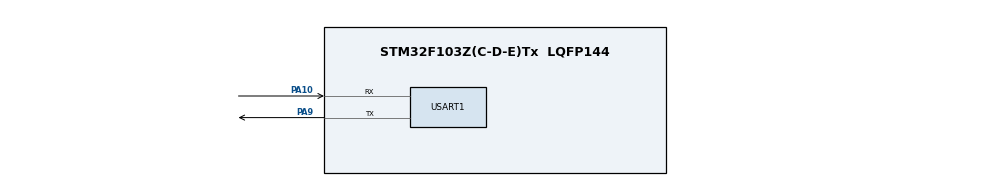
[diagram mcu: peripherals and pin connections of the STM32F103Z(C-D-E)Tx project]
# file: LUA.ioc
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Mcu.Family=STM32F1
Mcu.Name=STM32F103Z(C-D-E)Tx
Mcu.Package=LQFP144
NVIC.PriorityGroup=NVIC_PRIORITYGROUP_4
NVIC.USART1_IRQn=true\:0\:0\:false\:false\:true\:true\:true
OSC_IN.Mode=HSE-External-Oscillator
OSC_IN.Signal=RCC_OSC_IN
OSC_OUT.Mode=HSE-External-Oscillator
OSC_OUT.Signal=RCC_OSC_OUT
PA10.Mode=Asynchronous
PA10.Signal=USART1_RX
PA13.Mode=Serial_Wire
PA13.Signal=SYS_JTMS-SWDIO
PA14.Mode=Serial_Wire
PA14.Signal=SYS_JTCK-SWCLK
PA9.Mode=Asynchronous
PA9.Signal=USART1_TX
ProjectManager.HeapSize=0x200
ProjectManager.StackSize=0x400
ProjectManager.TargetToolchain=MDK-ARM V5
RCC.APB1Freq_Value=8000000
RCC.APB2Freq_Value=8000000
USART1.VirtualMode=VM_ASYNC
board=custom

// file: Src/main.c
/* USER CODE BEGIN Header */
/**
  ******************************************************************************
  * @file           : main.c
  * @brief          : Main program body
  ******************************************************************************
  * @attention
  *
  * <h2><center>&copy; Copyright (c) 2020 STMicroelectronics.
  * All rights reserved.</center></h2>
  *
  * This software component is licensed by ST under BSD 3-Clause license,
  * the "License"; You may not use this file except in compliance with the
  * License. You may obtain a copy of the License at:
  *                        opensource.org/licenses/BSD-3-Clause
  *
  ******************************************************************************
  */
/* USER CODE END Header */

#include "main.h"
#include "usart.h"
#include "gpio.h"

/* USER CODE BEGIN Includes */
#include "lua.h"
#include "lualib.h"
#include "lauxlib.h"
#include "string.h"
/* USER CODE END Includes */

/* USER CODE BEGIN PD */
#define LUA_MAXINPUT    512
#define LUA_PROMPT      "> "
#define LUA_PROMPT2     ">> "
/* USER CODE END PD */

void SystemClock_Config(void);

/* USER CODE BEGIN 0 */

/*
** lua_readline defines how to show a prompt and then read a line from
** the standard input.
** lua_saveline defines how to "save" a read line in a "history".
** lua_freeline defines how to free a line read by lua_readline.
*/
#if !defined(lua_readline)    /* { */

#define lua_readline(L,b,p) \
        ((void)L, fputs(p, stdout), fflush(stdout),  /* show prompt */ \
        fgets(b, LUA_MAXINPUT, stdin) != NULL)  /* get line */
#define lua_saveline(L,line)    { (void)L; (void)line; }
#define lua_freeline(L,b)    { (void)L; (void)b; }

#endif                /* } */

const char *progname = "lua";

/*
** Prints an error message, adding the program name in front of it
** (if present)
*/
static void l_message (const char *pname, const char *msg) {
    if (pname) printf("%s: ", pname);
    printf("%s\n", msg);
}

/*
** Message handler used to run all chunks
*/
static int msghandler (lua_State *L) {
    const char *msg = lua_tostring(L, 1);
    if (msg == NULL) {  /* is error object not a string? */
        if (luaL_callmeta(L, 1, "__tostring") &&  /* does it have a metamethod */
                lua_type(L, -1) == LUA_TSTRING)  /* that produces a string? */
            return 1;  /* that is the message */
        else
            msg = lua_pushfstring(L, "(error object is a %s value)",
                                  luaL_typename(L, 1));
    }
    luaL_traceback(L, L, msg, 1);  /* append a standard traceback */
    return 1;  /* return the traceback */
}

/*
** Check whether 'status' is not OK and, if so, prints the error
** message on the top of the stack. It assumes that the error object
** is a string, as it was either generated by Lua or by 'msghandler'.
*/
static int report (lua_State *L, int status) {
    if (status != LUA_OK) {
        const char *msg = lua_tostring(L, -1);
        l_message("lua", msg);
        lua_pop(L, 1);  /* remove message */
    }
    return status;
}

/*
** Interface to 'lua_pcall', which sets appropriate message function
** and C-signal handler. Used to run all chunks.
*/

static int docall (lua_State *L, int narg, int nres) {
    int status;
    int base = lua_gettop(L) - narg;  /* function index */
    lua_pushcfunction(L, msghandler);  /* push message handler */
    lua_insert(L, base);  /* put it under function and args */
    //globalL = L;  /* to be available to 'laction' */
    //signal(SIGINT, laction);  /* set C-signal handler */
    status = lua_pcall(L, narg, nres, base);
    //signal(SIGINT, SIG_DFL); /* reset C-signal handler */
    lua_remove(L, base);  /* remove message handler from the stack */
    return status;
}

static int dochunk (lua_State *L, int status) {
    if (status == LUA_OK) status = docall(L, 0, 0);
    return report(L, status);
}

static int dofile (lua_State *L, const char *name) {
    return dochunk(L, luaL_loadfile(L, name));
}

static int dostring (lua_State *L, const char *s, const char *name) {
    return dochunk(L, luaL_loadbuffer(L, s, strlen(s), name));
}

/*
** Returns the string to be used as a prompt by the interpreter.
*/
static const char *get_prompt (lua_State *L, int firstline) {
    const char *p;
    lua_getglobal(L, firstline ? "_PROMPT" : "_PROMPT2");
    p = lua_tostring(L, -1);
    if (p == NULL) p = (firstline ? LUA_PROMPT : LUA_PROMPT2);
    return p;
}

/* mark in error messages for incomplete statements */
#define EOFMARK        "<eof>"
#define marklen        (sizeof(EOFMARK)/sizeof(char) - 1)

/*
** Check whether 'status' signals a syntax error and the error
** message at the top of the stack ends with the above mark for
** incomplete statements.
*/
static int incomplete (lua_State *L, int status) {
    if (status == LUA_ERRSYNTAX) {
        size_t lmsg;
        const char *msg = lua_tolstring(L, -1, &lmsg);
        if (lmsg >= marklen && strcmp(msg + lmsg - marklen, EOFMARK) == 0) {
            lua_pop(L, 1);
            return 1;
        }
    }
    return 0;  /* else... */
}

/*
** Prompt the user, read a line, and push it into the Lua stack.
*/
static int pushline (lua_State *L, int firstline) {
    char buffer[LUA_MAXINPUT];
    char *b = buffer;
    size_t l;
    const char *prmt = get_prompt(L, firstline);
    int readstatus = lua_readline(L, b, prmt);
    if (readstatus == 0)
        return 0;  /* no input (prompt will be popped by caller) */
    lua_pop(L, 1);  /* remove prompt */
    l = strlen(b);
    if (l > 0 && b[l-1] == '\n')  /* line ends with newline? */
        b[--l] = '\0';  /* remove it */
    if (firstline && b[0] == '=')  /* for compatibility with 5.2, ... */
        lua_pushfstring(L, "return %s", b + 1);  /* change '=' to 'return' */
    else
        lua_pushlstring(L, b, l);
    lua_freeline(L, b);
    return 1;
}

/*
** Try to compile line on the stack as 'return <line>'; on return, stack
** has either compiled chunk or original line (if compilation failed).
*/
static int addreturn (lua_State *L) {
    int status;
    size_t len;
    const char *line;
    lua_pushliteral(L, "return ");
    lua_pushvalue(L, -2);  /* duplicate line */
    lua_concat(L, 2);  /* new line is "return ..." */
    line = lua_tolstring(L, -1, &len);
    if ((status = luaL_loadbuffer(L, line, len, "=stdin")) == LUA_OK) {
        lua_remove(L, -3);  /* remove original line */
        line += sizeof("return")/sizeof(char);  /* remove 'return' for history */
        if (line[0] != '\0')  /* non empty? */
            lua_saveline(L, line);  /* keep history */
    }
    else
        lua_pop(L, 2);  /* remove result from 'luaL_loadbuffer' and new line */
    return status;
}

/*
** Read multiple lines until a complete Lua statement
*/
static int multiline (lua_State *L) {
    for (;;) {  /* repeat until gets a complete statement */
        size_t len;
        const char *line = lua_tolstring(L, 1, &len);  /* get what it has */
        int status = luaL_loadbuffer(L, line, len, "=stdin");  /* try it */
        if (!incomplete(L, status) || !pushline(L, 0)) {
            lua_saveline(L, line);  /* keep history */
            return status;  /* cannot or should not try to add continuation line */
        }
        lua_pushliteral(L, "\n");  /* add newline... */
        lua_insert(L, -2);  /* ...between the two lines */
        lua_concat(L, 3);  /* join them */
    }
}

/*
** Read a line and try to load (compile) it first as an expression (by
** adding "return " in front of it) and second as a statement. Return
** the final status of load/call with the resulting function (if any)
** in the top of the stack.
*/
static int loadline (lua_State *L) {
    int status;
    lua_settop(L, 0);
    if (!pushline(L, 1))
        return -1;  /* no input */
    if ((status = addreturn(L)) != LUA_OK)  /* 'return ...' did not work? */
        status = multiline(L);  /* try as command, maybe with continuation lines */
    lua_remove(L, 1);  /* remove line from the stack */
    lua_assert(lua_gettop(L) == 1);
    return status;
}

/*
** Prints (calling the Lua 'print' function) any values on the stack
*/
static void l_print (lua_State *L) {
    int n = lua_gettop(L);
    if (n > 0) {  /* any result to be printed? */
        luaL_checkstack(L, LUA_MINSTACK, "too many results to print");
        lua_getglobal(L, "print");
        lua_insert(L, 1);
        if (lua_pcall(L, n, 0, 0) != LUA_OK)
            l_message(progname, lua_pushfstring(L, "error calling 'print' (%s)",
                                                lua_tostring(L, -1)));
    }
}

/*
** Do the REPL: repeatedly read (load) a line, evaluate (call) it, and
** print any results.
*/
static void doREPL (lua_State *L) {
    int status;
    const char *oldprogname = progname;
    progname = NULL;  /* no 'progname' on errors in interactive mode */
    while ((status = loadline(L)) != -1) {
        if (status == LUA_OK)
            status = docall(L, 0, LUA_MULTRET);
        if (status == LUA_OK) l_print(L);
        else report(L, status);
    }
    lua_settop(L, 0);  /* clear stack */
    lua_writeline();
    progname = oldprogname;
}

static void print_version (void) {
    lua_writestring(LUA_COPYRIGHT, strlen(LUA_COPYRIGHT));
    lua_writeline();
}

void lua_main(void)
{
    l_message("lua", "welcome !!!\n");
    lua_State *L = luaL_newstate();  /* create state */
    if (L == NULL) {
        l_message("lua", "cannot create state: not enough memory\n");
        return ;
    }
    luaL_openlibs(L);
    print_version();
    //dostring(L,"print('hello')","Test_lua");
    //dofile(L, NULL);  /* executes stdin as a file */
    doREPL(L);
    lua_close(L);
}

#ifdef __GNUC__
/* With GCC/RAISONANCE, small printf (option LD Linker->Libraries->Small printf
set to 'Yes') calls __io_putchar() */
#define PUTCHAR_PROTOTYPE int __io_putchar(int ch)
#else
#define PUTCHAR_PROTOTYPE int fputc(int ch, FILE *f)
#endif /* __GNUC__ */
/**
* @brief  Retargets the C library printf function to the USART.
* @param  None
* @retval None
*/
PUTCHAR_PROTOTYPE
{
    /* Place your implementation of fputc here */
    /* e.g. write a character to the EVAL_COM1 and Loop until the end of transmission */
    HAL_UART_Transmit(&huart1 , (uint8_t *)&ch, 1, 0xFFFF);

    return ch;
}

int fgetc(FILE *f)
{
    char ch = (char)-1;
    HAL_UART_Receive(&huart1 , (uint8_t *)&ch, 1, 0xFFFF);
    return (int)ch;
}
/* USER CODE END 0 */

int main(void)
{

    /* MCU Configuration--------------------------------------------------------*/

    /* Reset of all peripherals, Initializes the Flash interface and the Systick. */
    HAL_Init();

    /* Configure the system clock */
    SystemClock_Config();

    /* Initialize all configured peripherals */
    MX_GPIO_Init();
    MX_USART1_UART_Init();

    /* Infinite loop */
    /* USER CODE BEGIN WHILE */
    lua_main();
    while (1)
    {
        /* USER CODE END WHILE */

    }
}

void SystemClock_Config(void)
{
    RCC_OscInitTypeDef RCC_OscInitStruct = {0};
    RCC_ClkInitTypeDef RCC_ClkInitStruct = {0};

    /** Initializes the CPU, AHB and APB busses clocks
    */
    RCC_OscInitStruct.OscillatorType = RCC_OSCILLATORTYPE_HSI;
    RCC_OscInitStruct.HSIState = RCC_HSI_ON;
    RCC_OscInitStruct.HSICalibrationValue = RCC_HSICALIBRATION_DEFAULT;
    RCC_OscInitStruct.PLL.PLLState = RCC_PLL_NONE;
    if (HAL_RCC_OscConfig(&RCC_OscInitStruct) != HAL_OK)
    {
        Error_Handler();
    }
    /** Initializes the CPU, AHB and APB busses clocks
    */
    RCC_ClkInitStruct.ClockType = RCC_CLOCKTYPE_HCLK|RCC_CLOCKTYPE_SYSCLK
                                  |RCC_CLOCKTYPE_PCLK1|RCC_CLOCKTYPE_PCLK2;
    RCC_ClkInitStruct.SYSCLKSource = RCC_SYSCLKSOURCE_HSI;
    RCC_ClkInitStruct.AHBCLKDivider = RCC_SYSCLK_DIV1;
    RCC_ClkInitStruct.APB1CLKDivider = RCC_HCLK_DIV1;
    RCC_ClkInitStruct.APB2CLKDivider = RCC_HCLK_DIV1;

    if (HAL_RCC_ClockConfig(&RCC_ClkInitStruct, FLASH_LATENCY_0) != HAL_OK)
    {
        Error_Handler();
    }
}

void Error_Handler(void)
{
}

/************************ (C) COPYRIGHT STMicroelectronics *****END OF FILE****/
